VERSION ""

NS_ :

BS_:

BU_: XXX

BO_ 85 CID_TUHVIT: 8 XXX
 SG_ sig_lyhqtv : 40|1@1+ (1,0) [0|1] "" XXX
 SG_ sig_thkwwo : 56|8@1+ (1,0) [0|255] "" XXX

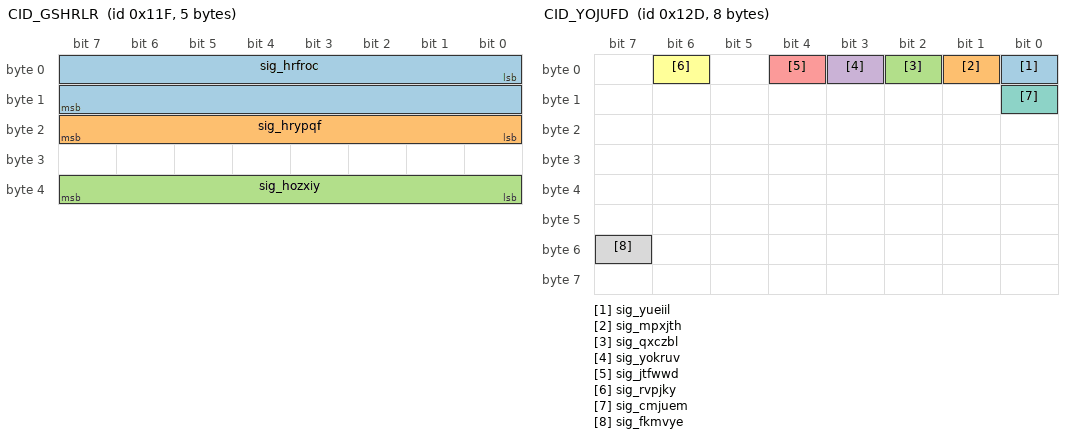
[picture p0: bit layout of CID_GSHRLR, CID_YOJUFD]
BO_ 287 CID_GSHRLR: 5 XXX
 SG_ sig_hrfroc : 0|16@1- (0.1,0) [-450|450] "" XXX
 SG_ sig_hrypqf : 16|8@1+ (4,0) [0|1020] "" XXX
 SG_ sig_hozxiy : 32|8@1+ (1,0) [0|255] "" XXX

BO_ 289 CID_LYWELQ: 8 XXX
 SG_ sig_ufgmik : 0|12@1+ (1,0) [0|255] "" XXX

BO_ 301 CID_YOJUFD: 8 XXX
 SG_ sig_yueiil : 0|1@0+ (1,0) [0|1] "" XXX
 SG_ sig_mpxjth : 1|1@0+ (1,0) [0|1] "" XXX
 SG_ sig_qxczbl : 2|1@0+ (1,0) [0|1] "" XXX
 SG_ sig_yokruv : 3|1@0+ (1,0) [0|1] "" XXX
 SG_ sig_jtfwwd : 4|1@0+ (1,0) [0|1] "" XXX
 SG_ sig_rvpjky : 6|1@0+ (1,0) [0|1] "" XXX
 SG_ sig_cmjuem : 8|1@0+ (1,0) [0|1] "" XXX
 SG_ sig_fkmvye : 55|1@0+ (1,0) [0|1] "" XXX

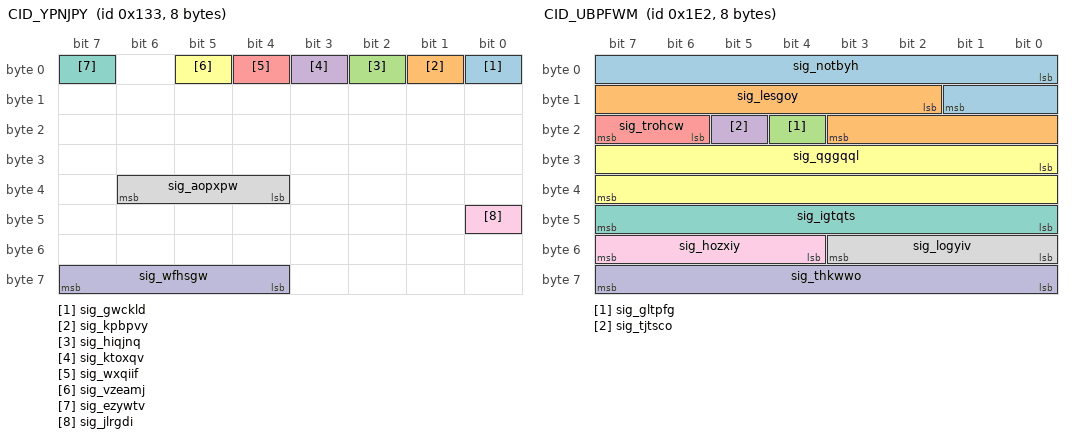
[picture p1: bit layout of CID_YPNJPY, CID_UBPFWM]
BO_ 307 CID_YPNJPY: 8 XXX
 SG_ sig_gwckld : 0|1@0+ (1,0) [0|1] "" XXX
 SG_ sig_kpbpvy : 1|1@1+ (1,0) [0|1] "" XXX
 SG_ sig_hiqjnq : 2|1@1+ (1,0) [0|1] "" XXX
 SG_ sig_ktoxqv : 3|1@1+ (1,0) [0|1] "" XXX
 SG_ sig_wxqiif : 4|1@0+ (1,0) [0|1] "" XXX
 SG_ sig_vzeamj : 5|1@0+ (1,0) [0|1] "" XXX
 SG_ sig_ezywtv : 7|1@0+ (1,0) [0|1] "" XXX
 SG_ sig_aopxpw : 36|3@1+ (1,0) [0|7] "" XXX
 SG_ sig_jlrgdi : 40|1@0+ (1,0) [0|1] "" XXX
 SG_ sig_wfhsgw : 63|4@0+ (1,0) [0|15] "" XXX

BO_ 482 CID_UBPFWM: 8 XXX
 SG_ sig_notbyh : 0|10@1- (0.01,0) [0|5] "" XXX
 SG_ sig_lesgoy : 10|10@1- (0.01,0) [-5|0] "" XXX
 SG_ sig_gltpfg : 20|1@0+ (1,0) [0|1] "" XXX
 SG_ sig_tjtsco : 21|1@0+ (1,0) [0|1] "" XXX
 SG_ sig_trohcw : 22|2@1+ (1,0) [0|1] "" XXX
 SG_ sig_qggqql : 24|16@1- (0.1,0) [-780|779.9] "" XXX
 SG_ sig_igtqts : 47|8@0+ (1,0) [0|255] "" XXX
 SG_ sig_logyiv : 48|4@1+ (1,0) [0|15] "" XXX
 SG_ sig_hozxiy : 52|4@1+ (1,0) [0|15] "" XXX
 SG_ sig_thkwwo : 56|8@1+ (1,0) [0|255] "" XXX

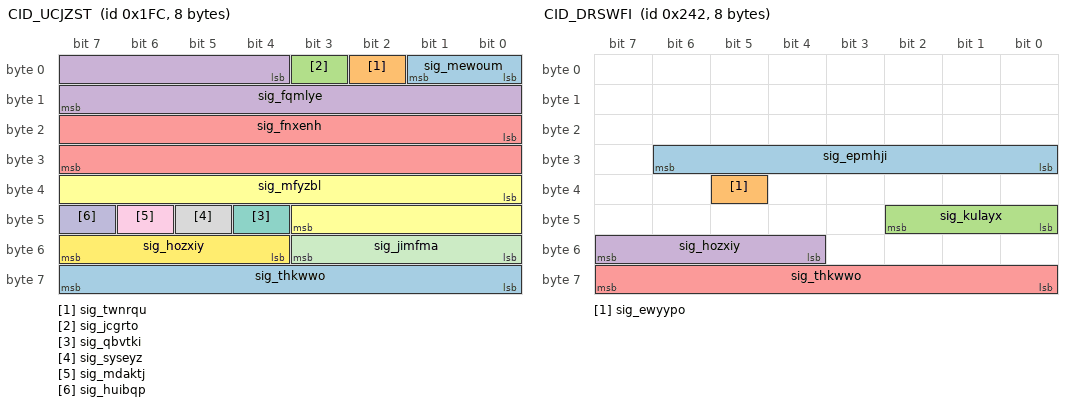
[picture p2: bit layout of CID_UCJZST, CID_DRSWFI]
BO_ 508 CID_UCJZST: 8 XXX
 SG_ sig_mewoum : 0|2@1+ (1,0) [0|1] "" XXX
 SG_ sig_twnrqu : 2|1@1+ (1,0) [0|1] "" XXX
 SG_ sig_jcgrto : 3|1@0+ (1,0) [0|1] "" XXX
 SG_ sig_fqmlye : 4|12@1- (1,0) [-2048|2047] "" XXX
 SG_ sig_fnxenh : 16|16@1- (0.1,0) [-780|779.9] "Deg" XXX
 SG_ sig_mfyzbl : 32|12@1- (0.01,0) [0|63] "" XXX
 SG_ sig_qbvtki : 44|1@0+ (1,0) [0|1] "" XXX
 SG_ sig_syseyz : 45|1@1+ (1,0) [0|255] "" XXX
 SG_ sig_mdaktj : 46|1@1+ (1,0) [0|1] "" XXX
 SG_ sig_huibqp : 47|1@0+ (1,0) [0|3] "" XXX
 SG_ sig_jimfma : 48|4@1+ (1,0) [0|15] "" XXX
 SG_ sig_hozxiy : 52|4@1+ (1,0) [0|15] "" XXX
 SG_ sig_thkwwo : 56|8@1+ (1,0) [0|255] "" XXX

BO_ 578 CID_DRSWFI: 8 XXX
 SG_ sig_epmhji : 30|7@0+ (1,0) [0|127] "" XXX
 SG_ sig_ewyypo : 37|1@0+ (1,0) [0|1] "" XXX
 SG_ sig_kulayx : 40|3@1+ (1,0) [0|7] "" XXX
 SG_ sig_hozxiy : 55|4@0+ (1,0) [0|15] "" XXX
 SG_ sig_thkwwo : 56|8@1+ (1,0) [0|255] "" XXX

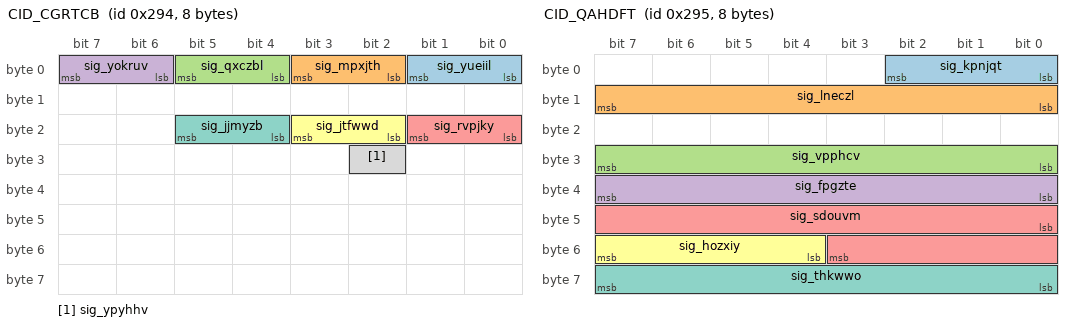
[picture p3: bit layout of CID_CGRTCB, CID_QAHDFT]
BO_ 660 CID_CGRTCB: 8 XXX
 SG_ sig_yueiil : 1|2@0+ (1,0) [0|3] "" XXX
 SG_ sig_mpxjth : 3|2@0+ (1,0) [0|3] "" XXX
 SG_ sig_qxczbl : 5|2@0+ (1,0) [0|3] "" XXX
 SG_ sig_yokruv : 7|2@0+ (1,0) [0|3] "" XXX
 SG_ sig_rvpjky : 17|2@0+ (1,0) [0|3] "" XXX
 SG_ sig_jtfwwd : 19|2@0+ (1,0) [0|3] "" XXX
 SG_ sig_jjmyzb : 21|2@0+ (1,0) [0|3] "" XXX
 SG_ sig_ypyhhv : 26|1@0+ (1,0) [0|1] "" XXX

BO_ 661 CID_QAHDFT: 8 XXX
 SG_ sig_kpnjqt : 2|3@0+ (1,0) [0|7] "" XXX
 SG_ sig_lneczl : 15|8@0+ (1,0) [0|255] "" XXX
 SG_ sig_vpphcv : 31|8@0+ (1,0) [0|255] "" XXX
 SG_ sig_fpgzte : 32|8@1+ (1,0) [0|255] "" XXX
 SG_ sig_sdouvm : 40|12@1+ (1,0) [0|255] "" XXX
 SG_ sig_hozxiy : 52|4@1+ (1,0) [0|15] "" XXX
 SG_ sig_thkwwo : 63|8@0+ (1,0) [0|255] "" XXX

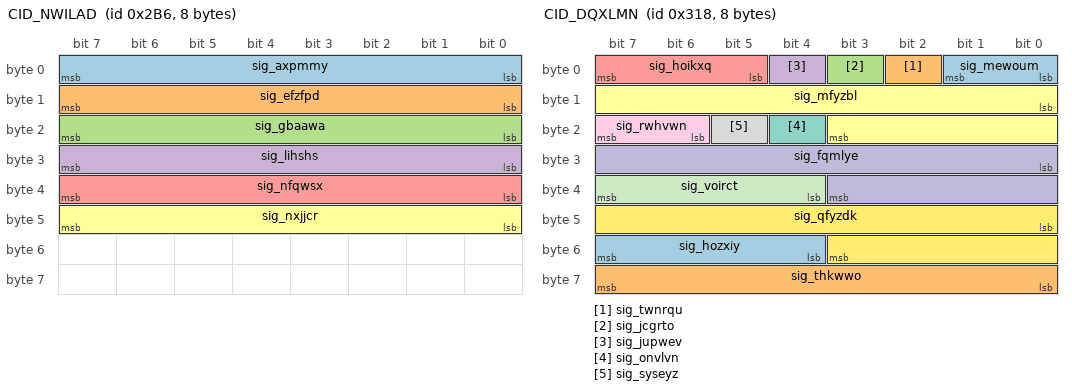
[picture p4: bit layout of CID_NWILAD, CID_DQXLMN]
BO_ 694 CID_NWILAD: 8 XXX
 SG_ sig_axpmmy : 7|8@0+ (1,0) [0|255] "" XXX
 SG_ sig_efzfpd : 15|8@0+ (1,0) [0|255] "" XXX
 SG_ sig_gbaawa : 23|8@0+ (1,0) [0|255] "" XXX
 SG_ sig_lihshs : 31|8@0+ (1,0) [0|255] "" XXX
 SG_ sig_nfqwsx : 39|8@0+ (1,0) [0|255] "" XXX
 SG_ sig_nxjjcr : 47|8@0+ (1,0) [0|255] "" XXX

BO_ 790 CID_DXNCXB: 8 XXX
 SG_ sig_avhpnn : 3|4@0+ (1,0) [0|1] "" XXX
 SG_ sig_swblma : 4|2@1+ (1,0) [0|3] "" XXX
 SG_ sig_jasfna : 6|2@1+ (1,0) [0|3] "" XXX
 SG_ sig_lvmepe : 8|2@1+ (1,0) [0|3] "" XXX
 SG_ sig_ivescx : 10|1@1+ (1,0) [0|1] "" XXX
 SG_ sig_xpqvui : 11|4@1+ (1,0) [0|1] "" XXX
 SG_ sig_snihno : 15|1@0+ (1,0) [0|1] "" XXX
 SG_ sig_qggqql : 16|11@1- (1,0) [-1024|1023] "" XXX
 SG_ sig_gltpfg : 27|1@1+ (1,0) [0|1] "" XXX
 SG_ sig_tjtsco : 28|1@1+ (1,0) [0|3] "" XXX
 SG_ sig_txetdx : 29|1@0+ (1,0) [0|1] "" XXX
 SG_ sig_viqrbz : 30|1@0+ (1,0) [0|1] "" XXX
 SG_ sig_wllrrx : 31|1@0+ (1,0) [0|1] "" XXX
 SG_ sig_qfatjp : 32|2@1+ (1,0) [0|3] "" XXX
 SG_ sig_qaznmo : 34|2@1+ (1,0) [0|3] "" XXX
 SG_ sig_pxsubz : 36|4@1+ (1,0) [0|3] "" XXX
 SG_ sig_pawkif : 40|8@1+ (5,-5) [-5|1270] "" XXX
 SG_ sig_lirehm : 49|2@0+ (1,0) [0|3] "" XXX
 SG_ sig_xqgqap : 51|2@0+ (1,0) [0|3] "" XXX
 SG_ sig_hozxiy : 52|4@1+ (1,0) [0|15] "" XXX
 SG_ sig_thkwwo : 56|8@1+ (1,0) [0|15] "" XXX

BO_ 792 CID_DQXLMN: 8 XXX
 SG_ sig_mewoum : 0|2@1+ (1,0) [0|1] "" XXX
 SG_ sig_twnrqu : 2|1@1+ (1,0) [0|1] "" XXX
 SG_ sig_jcgrto : 3|1@1+ (1,0) [0|1] "" XXX
 SG_ sig_jupwev : 4|1@1+ (1,0) [0|1] "" XXX
 SG_ sig_hoikxq : 5|3@1+ (1,0) [0|1] "" XXX
 SG_ sig_mfyzbl : 8|12@1- (1,0) [-2048|2047] "" XXX
 SG_ sig_onvlvn : 20|1@1+ (1,0) [0|1] "" XXX
 SG_ sig_syseyz : 21|1@1+ (1,0) [0|1] "" XXX
 SG_ sig_rwhvwn : 22|2@1+ (1,0) [0|15] "" XXX
 SG_ sig_fqmlye : 24|12@1- (1,0) [-2048|2047] "" XXX
 SG_ sig_voirct : 36|4@1+ (1,0) [0|15] "" XXX
 SG_ sig_qfyzdk : 40|12@1+ (1,0) [0|4095] "" XXX
 SG_ sig_hozxiy : 52|4@1+ (1,0) [0|15] "" XXX
 SG_ sig_thkwwo : 56|8@1+ (1,0) [0|255] "" XXX

BO_ 813 CID_TVYVDF: 8 XXX
 SG_ sig_tuvbdd : 0|9@1+ (0.5,0) [0|255.5] "" XXX
 SG_ sig_dhctzk : 9|1@1+ (1,0) [0|1] "" XXX
 SG_ sig_qnpleb : 10|3@1+ (1,0) [0|7] "" XXX
 SG_ sig_nttzsk : 13|3@1+ (1,0) [0|7] "" XXX
 SG_ sig_jgdryl : 16|1@1+ (1,0) [0|1] "" XXX
 SG_ sig_jvretm : 17|1@1+ (1,0) [0|1] "" XXX
 SG_ sig_jcgrto : 18|1@1+ (1,0) [0|1] "" XXX
 SG_ sig_ynlfbq : 19|3@1+ (1,0) [0|1] "" XXX
 SG_ sig_gowyty : 22|1@0+ (1,0) [0|1] "" XXX
 SG_ sig_lajfij : 23|1@0+ (1,0) [0|1] "" XXX
 SG_ sig_lvmepe : 24|1@1+ (1,0) [0|1] "" XXX
 SG_ sig_xwyvhx : 25|7@1+ (1,0) [0|127] "" XXX
 SG_ sig_tzcikg : 32|4@1+ (1,0) [0|15] "" XXX
 SG_ sig_gvthfz : 36|12@1+ (1,0) [0|4095] "" XXX
 SG_ sig_hozxiy : 48|4@1+ (1,0) [0|15] "" XXX
 SG_ sig_kqhzpo : 55|4@0+ (1,0) [0|15] "" XXX
 SG_ sig_thkwwo : 56|8@1+ (1,0) [0|255] "" XXX

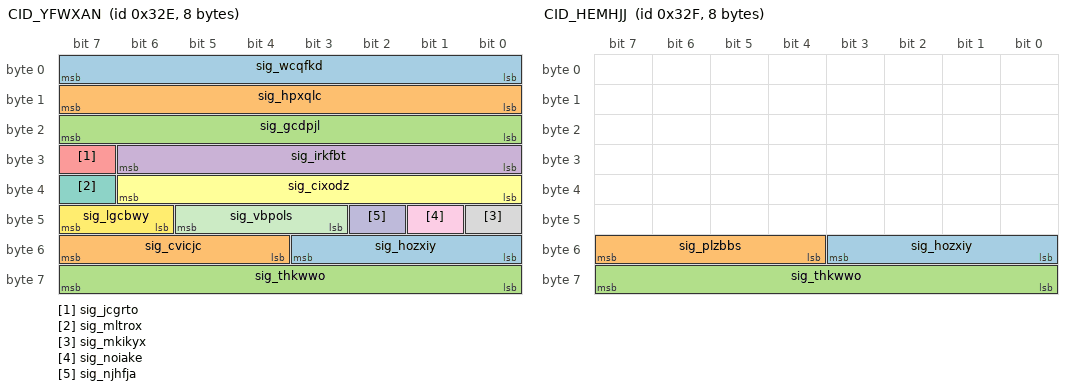
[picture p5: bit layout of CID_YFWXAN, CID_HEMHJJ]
BO_ 814 CID_YFWXAN: 8 XXX
 SG_ sig_wcqfkd : 0|8@1+ (0.05,-5) [-100|155] "" XXX
 SG_ sig_hpxqlc : 8|8@1+ (0.05,-5) [0|1.26] "" XXX
 SG_ sig_gcdpjl : 16|8@1+ (0.05,-5) [0|1.26] "" XXX
 SG_ sig_irkfbt : 24|7@1+ (0.2,0) [0|12.7] "" XXX
 SG_ sig_jcgrto : 31|1@0+ (1,0) [0|1] "" XXX
 SG_ sig_cixodz : 32|7@1+ (0.2,-16) [0|12.7] "" XXX
 SG_ sig_mltrox : 39|1@0+ (1,0) [0|1] "" XXX
 SG_ sig_mkikyx : 40|1@0+ (1,0) [0|1] "" XXX
 SG_ sig_noiake : 41|1@0+ (1,0) [0|1] "" XXX
 SG_ sig_njhfja : 42|1@1+ (1,0) [0|3] "" XXX
 SG_ sig_vbpols : 45|3@0+ (1,0) [0|1] "" XXX
 SG_ sig_lgcbwy : 46|2@1+ (1,0) [0|3] "" XXX
 SG_ sig_hozxiy : 48|4@1+ (1,0) [0|15] "" XXX
 SG_ sig_cvicjc : 55|4@0+ (1,0) [0|15] "" XXX
 SG_ sig_thkwwo : 56|8@1+ (1,0) [0|255] "" XXX

BO_ 815 CID_HEMHJJ: 8 XXX
 SG_ sig_hozxiy : 48|4@1+ (1,0) [0|15] "" XXX
 SG_ sig_plzbbs : 55|4@0+ (1,0) [0|15] "" XXX
 SG_ sig_thkwwo : 56|8@1+ (1,0) [0|255] "" XXX

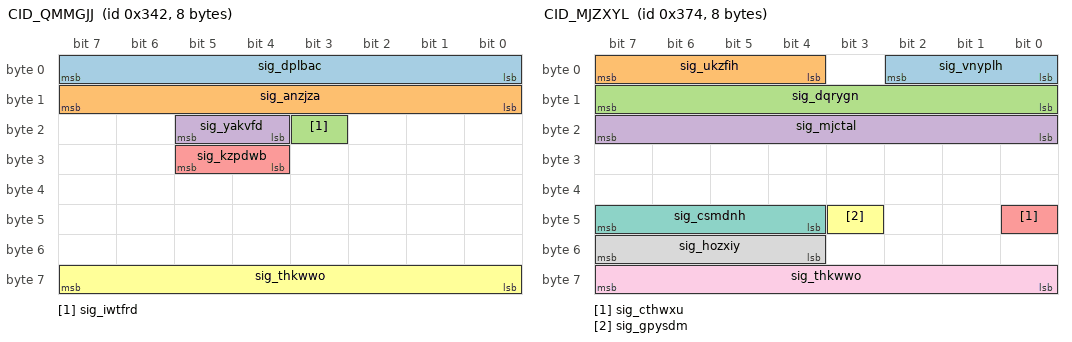
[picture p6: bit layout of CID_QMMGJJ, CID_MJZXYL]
BO_ 834 CID_QMMGJJ: 8 XXX
 SG_ sig_dplbac : 0|8@1+ (0.01,0) [0|2.55] "" XXX
 SG_ sig_anzjza : 8|8@1+ (0.01,0) [0|2.55] "" XXX
 SG_ sig_iwtfrd : 19|1@1+ (1,0) [0|1] "" XXX
 SG_ sig_yakvfd : 20|2@1+ (1,0) [0|255] "" XXX
 SG_ sig_kzpdwb : 28|2@1+ (1,0) [0|1] "" XXX
 SG_ sig_thkwwo : 56|8@1+ (1,0) [0|255] "" XXX

 BO_ 884 CID_MJZXYL: 8 MRR
 SG_ sig_vnyplh : 2|3@0+ (1,0) [0|3] "" MRR
 SG_ sig_ukzfih : 7|4@0+ (1,0) [0|15] "" MRR
 SG_ sig_dqrygn : 15|8@0+ (0.1,-12) [0|255] "" MRR
 SG_ sig_mjctal : 23|8@0+ (1,-100) [0|255] "" MRR
 SG_ sig_cthwxu : 40|1@0+ (1,0) [0|3] "" MRR
 SG_ sig_gpysdm : 43|1@0+ (1,0) [0|1] "" XXX
 SG_ sig_csmdnh : 44|4@1+ (1,0) [0|15] "" XXX
 SG_ sig_hozxiy : 52|4@1+ (1,0) [0|15] "" MRR
 SG_ sig_thkwwo : 56|8@1+ (1,0) [0|255] "" MRR

BO_ 944 CID_GIYBTM: 8 XXX
 SG_ sig_tuqtob : 1|2@0+ (1,0) [0|3] "" XXX
 SG_ sig_zjuart : 2|1@0+ (1,0) [0|1] "" XXX
 SG_ sig_iupibb : 4|2@0+ (1,0) [0|3] "" XXX
 SG_ sig_yegvpf : 5|1@0+ (1,0) [0|1] "" XXX
 SG_ sig_iamrot : 6|1@0+ (1,0) [0|1] "" XXX
 SG_ sig_ssfail : 7|1@0+ (1,0) [0|1] "" XXX
 SG_ sig_uskjzn : 8|1@0+ (1,0) [0|1] "" XXX
 SG_ sig_xklihq : 11|3@0+ (1,0) [0|7] "" XXX
 SG_ sig_fwgzsp : 12|1@0+ (1,0) [0|1] "" XXX
 SG_ sig_yqseti : 14|2@0+ (1,0) [0|3] "" XXX
 SG_ sig_lheoti : 15|1@0+ (1,0) [0|1] "" XXX
 SG_ sig_ipcoqs : 16|1@0+ (1,0) [0|1] "" XXX
 SG_ sig_ojirst : 18|2@0+ (1,0) [0|3] "" XXX
 SG_ sig_rinnap : 19|1@0+ (1,0) [0|1] "" XXX
 SG_ sig_fydbif : 23|4@0+ (1,0) [0|15] "" XXX
 SG_ sig_yjlnlo : 24|28@1+ (1,0) [0|268435455] "" XXX
 SG_ sig_hozxiy : 52|4@1+ (1,0) [0|15] "" XXX
 SG_ sig_thkwwo : 56|8@1+ (1,0) [0|255] "" XXX

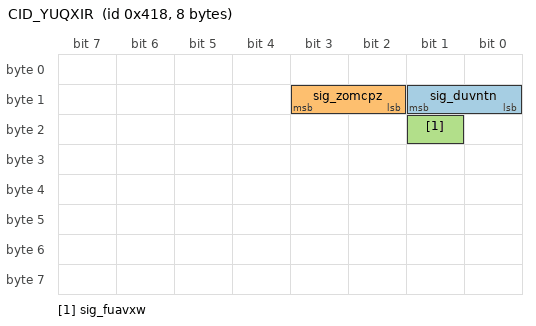
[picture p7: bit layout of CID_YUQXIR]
BO_ 1048 CID_YUQXIR: 8 XXX
 SG_ sig_duvntn : 9|2@0+ (1,0) [0|1] "" XXX
 SG_ sig_zomcpz : 11|2@0+ (1,0) [0|1] "" XXX
 SG_ sig_fuavxw : 17|1@0+ (1,0) [0|1] "" XXX

VAL_ 578 sig_kulayx 4 "D" 2 "R" 3 "N" 1 "P";
VAL_ 790 sig_avhpnn 11 "AutoFullBeamActive" 2 "AutoFullBeamInactive";
VAL_ 790 sig_swblma 0 "GRAY" 1 "GREEN" 2 "YELLOW" 3 "RED";
VAL_ 790 sig_jasfna 3 "ALARM_AND_LKA" 2 "LKA" 1 "ALARM" 0 "DISABLE";
VAL_ 790 sig_qaznmo 0 "GRAY" 1 "GREEN" 2 "YELLOW" 3 "RED";
VAL_ 790 sig_lirehm 0 "VIBRATION" 1 "AUDIO" 2 "AUDIO_AND_VIBRATION";
VAL_ 792 sig_mewoum 0 "NotReady" 1 "Ready" 2 "Active" 3 "TemporaryFail";
VAL_ 813 sig_qnpleb 4 "4BAR" 3 "3BAR" 2 "2BAR" 1 "1BAR";
VAL_ 813 sig_ynlfbq 0 "OFF" 2 "ACC_ON" 3 "ACC_ACTIVE" 5 "FORCE_ACCEL" 7 "ERROR";
VAL_ 813 sig_xwyvhx 36 "ACC_ERROR" 22 "OVERRIDE" 12 "ENGAGE" 8 "DISENGAGE" 20 "ACC_ON" 32 "ACC_OFF" 48 "CHECK_GEAR_D" 16 "FORCE_ACCEL" 0 "NONE";
VAL_ 814 sig_vbpols 0 "Off" 1 "Passive" 2 "StandBy" 3 "ActiveControl" 4 "BrakeOnly" 5 "Override" 6 "Standstill" 7 "Failure";
VAL_ 814 sig_lgcbwy 0 "Softoff" 1 "Fastoff" 2 "Immediateoff" 3 "Initial";
VAL_ 834 sig_yakvfd 2 "SPORT" 1 "ECO" 0 "SNOW";
VAL_ 834 sig_kzpdwb 3 "HEV" 2 "FORCE_EV" 1 "EV";
VAL_ 944 sig_iupibb 0 "NOTPRESSED" 1 "DOWN_SETSPEED" 3 "UP_RESETSPEED";
